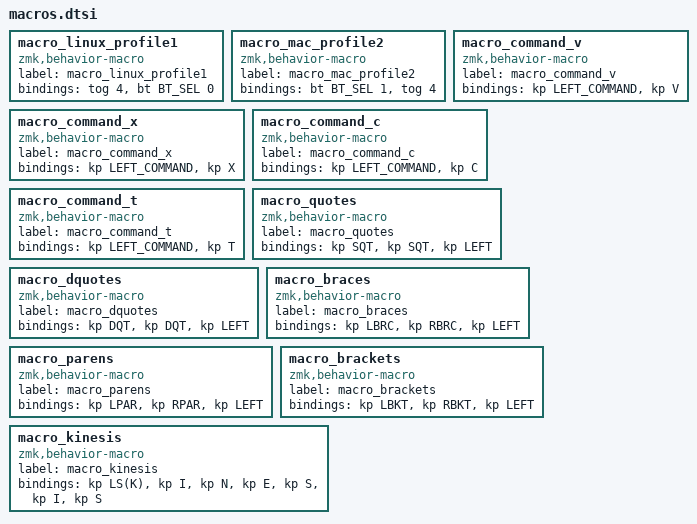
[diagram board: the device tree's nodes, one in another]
macro_linux_profile1: macro_linux_profile1{
compatible = "zmk,behavior-macro";
label = "macro_linux_profile1";
#binding-cells = <0>;
bindings = <&tog 4>, <&bt BT_SEL 0>;
};
macro_mac_profile2: macro_mac_profile2{
compatible = "zmk,behavior-macro";
label = "macro_mac_profile2";
#binding-cells = <0>;
bindings = <&bt BT_SEL 1>, <&tog 4>;
};
macro_command_v: macro_command_v{
compatible = "zmk,behavior-macro";
label = "macro_command_v";
#binding-cells = <0>;
bindings = <&kp LEFT_COMMAND>, <&kp V>;
};
macro_command_x: macro_command_x{
compatible = "zmk,behavior-macro";
label = "macro_command_x";
#binding-cells = <0>;
bindings = <&kp LEFT_COMMAND>, <&kp X>;
};
macro_command_c: macro_command_c{
compatible = "zmk,behavior-macro";
label = "macro_command_c";
#binding-cells = <0>;
bindings = <&kp LEFT_COMMAND>, <&kp C>;
};
macro_command_t: macro_command_t{
compatible = "zmk,behavior-macro";
label = "macro_command_t";
#binding-cells = <0>;
bindings = <&kp LEFT_COMMAND>, <&kp T>;
};
macro_quotes: macro_quotes{
compatible = "zmk,behavior-macro";
label = "macro_quotes";
#binding-cells = <0>;
bindings = <&kp SQT>, <&kp SQT>, <&kp LEFT>;
};
macro_dquotes: macro_dquotes{
compatible = "zmk,behavior-macro";
label = "macro_dquotes";
#binding-cells = <0>;
bindings = <&kp DQT>, <&kp DQT>, <&kp LEFT>;
};
macro_braces: macro_braces{
compatible = "zmk,behavior-macro";
label = "macro_braces";
#binding-cells = <0>;
bindings = <&kp LBRC>, <&kp RBRC>, <&kp LEFT>;
};
macro_parens: macro_parens{
compatible = "zmk,behavior-macro";
label = "macro_parens";
#binding-cells = <0>;
bindings = <&kp LPAR>, <&kp RPAR>, <&kp LEFT>;
};
macro_brackets: macro_brackets{
compatible = "zmk,behavior-macro";
label = "macro_brackets";
#binding-cells = <0>;
bindings = <&kp LBKT>, <&kp RBKT>, <&kp LEFT>;
};
macro_kinesis: macro_kinesis{
compatible = "zmk,behavior-macro";
label = "macro_kinesis";
#binding-cells = <0>;
bindings = <&kp LS(K)>, <&kp I>, <&kp N>, <&kp E>, <&kp S>, <&kp I>, <&kp S>;
};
